# ESP32S31_RADIO register map
Vendor: Espressif; Series: ESP32-S31; File version: 3.52
Registers are 32-bit, read-write, no defined reset value unless marked. A register's access mark holds for its fields unless they carry their own. Offsets are from the block's base; [hi:lo] are bit positions; {n}, {i} and the like mark numbered series; 'fields as' and 'values as' point back to an identical list.

## BT_V3_2_CTE — Bluetooth direction-finding control words recovered from complete, independently named CTE accessors in the ESP32-S31 vendor baseband library. Only fields touched by those accessors are described; untouched bits remain unassigned.
Base 0x20102000
0x94 LC_8M_CONTROL — Bluetooth CTE LC 8-Mbit enable control.
  [0] LC_8M_ENABLE — The matched getter/setter pair reads and replaces bit 0.
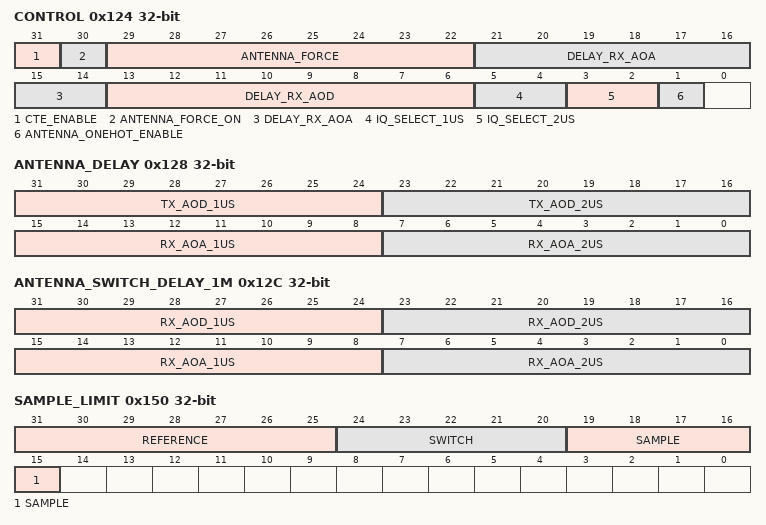
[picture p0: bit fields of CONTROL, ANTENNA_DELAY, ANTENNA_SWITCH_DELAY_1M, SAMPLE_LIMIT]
0x124 CONTROL — CTE antenna selection, receive-delay, IQ-selection and enable control. Bit 0 remains unassigned.
  [31] CTE_ENABLE — Complete ble_bb_cte_set_cte_en replaces bit 31 with the caller's Boolean image.
  [30] ANTENNA_FORCE_ON
  [29:22] ANTENNA_FORCE
  [21:14] DELAY_RX_AOA
  [13:6] DELAY_RX_AOD
  [5:4] IQ_SELECT_1US
  [3:2] IQ_SELECT_2US
  [1] ANTENNA_ONEHOT_ENABLE
0x128 ANTENNA_DELAY — Four independent eight-bit antenna delays selected by CTE direction and slot duration.
  [31:24] TX_AOD_1US, [23:16] TX_AOD_2US, [15:8] RX_AOA_1US, [7:0] RX_AOA_2US
0x12C ANTENNA_SWITCH_DELAY_1M — Four independent antenna-switch delays used by the ordinary CTE accessors.
  [31:24] RX_AOD_1US, [23:16] RX_AOD_2US, [15:8] RX_AOA_1US, [7:0] RX_AOA_2US
{0x130+2i} ANTENNA_MAP_ENTRY{i} (i=0..15) 16-bit wo — First sixteen halfword slots of the indexed antenna-map window. The complete setter copies caller-provided halfwords from index zero up to its input count; sixteen slots are the exact finite effects recovered under the current analysis bound, not a claim that the hardware window ends here.
  [15:0] IMAGE — Complete 16-bit antenna-map element; the encoding remains unknown.
0x150 SAMPLE_LIMIT — Three independently readable and writable CTE sampling-limit fields.
  [31:25] REFERENCE, [24:20] SWITCH, [19:15] SAMPLE
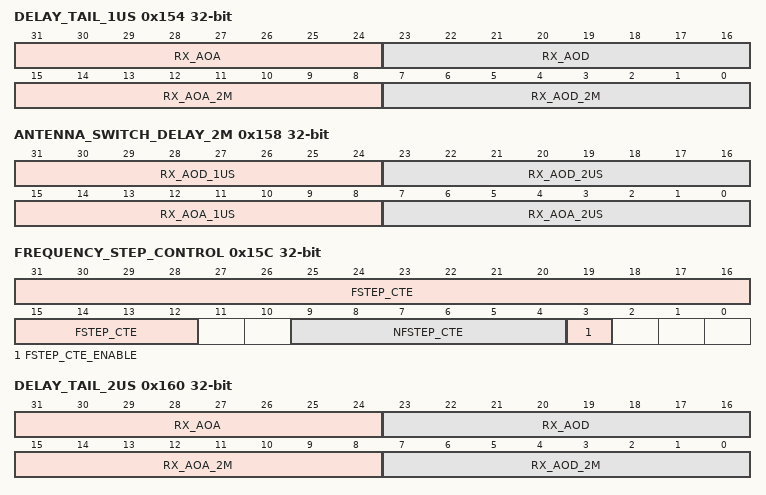
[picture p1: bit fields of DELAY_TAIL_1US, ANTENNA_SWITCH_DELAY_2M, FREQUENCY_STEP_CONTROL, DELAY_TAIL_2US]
0x154 DELAY_TAIL_1US — Four independent receive-tail delays for ordinary and 2-Mbit CTE operation with 1-microsecond slots.
  [31:24] RX_AOA, [23:16] RX_AOD, [15:8] RX_AOA_2M, [7:0] RX_AOD_2M
0x158 ANTENNA_SWITCH_DELAY_2M — Four independent antenna-switch delays used by the explicit 2-Mbit CTE accessors.
  fields as ANTENNA_SWITCH_DELAY_1M
0x15C FREQUENCY_STEP_CONTROL — CTE frequency-step enable, count and 20-bit step image. Bits 0:2 and 10:11 remain unassigned.
  [31:12] FSTEP_CTE, [9:4] NFSTEP_CTE, [3] FSTEP_CTE_ENABLE
0x160 DELAY_TAIL_2US — Four independent receive-tail delays for ordinary and 2-Mbit CTE operation with 2-microsecond slots.
  [31:24] RX_AOA, [23:16] RX_AOD, [15:8] RX_AOA_2M, [7:0] RX_AOD_2M
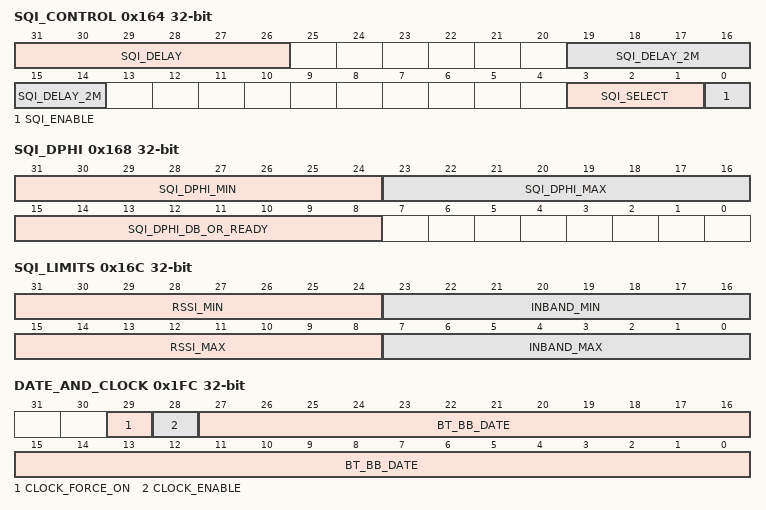
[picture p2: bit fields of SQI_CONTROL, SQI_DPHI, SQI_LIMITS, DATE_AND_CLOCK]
0x164 SQI_CONTROL — CTE signal-quality-indicator enable, selector and per-rate delay fields.
  [31:26] SQI_DELAY, [19:14] SQI_DELAY_2M, [3:1] SQI_SELECT, [0] SQI_ENABLE
0x168 SQI_DPHI — CTE SQI phase-difference thresholds/status. The byte at bits 15:8 is exposed both as SQI_DPHI_DB and, independently, bit 14 as SQI_READY; the non-overlapping model preserves that exact alias in one combined field.
  [31:24] SQI_DPHI_MIN
  [23:16] SQI_DPHI_MAX
  [15:8] SQI_DPHI_DB_OR_READY — Eight-bit SQI_DPHI_DB image; bit 6 of this field is also the independently addressable SQI_READY bit.
0x16C SQI_LIMITS — Four independent eight-bit in-band and RSSI thresholds used by the CTE SQI logic.
  [31:24] RSSI_MIN, [23:16] INBAND_MIN, [15:8] RSSI_MAX, [7:0] INBAND_MAX
0x1FC DATE_AND_CLOCK — Bluetooth baseband date image and CTE clock gates. Bits 31:30 remain unassigned.
  [29] CLOCK_FORCE_ON, [28] CLOCK_ENABLE, [27:0] BT_BB_DATE ro

## ZBBB_RADIO_CONTROL — Independently bounded words in the ZBBB window touched by complete Bluetooth baseband receive-setup and reset-idle leaves. Names describe only those exact operations; they do not claim that the physical block is owned exclusively by Bluetooth or assign a wider ZBBB protocol meaning.
Base 0x20102C00
0x00 RX_SETUP_IMAGE — bt_bb_rx_set preserves the low 12 bits and replaces bits 31:12 with the finite image 0x001CB; after the shared receive prefix, bt_bb_v2_init_cmplx(1) independently replaces the same field with 0x0019F.
  [31:12] CONFIG_IMAGE
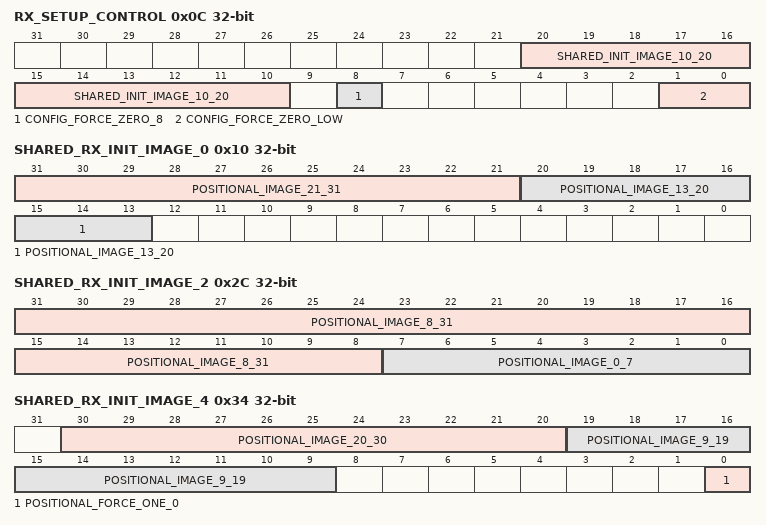
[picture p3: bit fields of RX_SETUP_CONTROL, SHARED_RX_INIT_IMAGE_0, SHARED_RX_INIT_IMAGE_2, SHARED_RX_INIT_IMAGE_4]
0x0C RX_SETUP_CONTROL — bt_bb_rx_set clears bit 8 and the low two-bit field through separate fresh-read RMW operations; the complete shared receive initializer independently replaces bits 10:20.
  [20:10] SHARED_INIT_IMAGE_10_20 — The complete shared receive initializer replaces bits 10:20 with the finite image 0x79C.
  [8] CONFIG_FORCE_ZERO_8
  [1:0] CONFIG_FORCE_ZERO_LOW
0x10 SHARED_RX_INIT_IMAGE_0 — The complete shared receive initializer replaces two disjoint positional fields with finite images while preserving every other bit.
  [31:21] POSITIONAL_IMAGE_21_31 — The complete initializer replaces bits 21:31 with the finite image 0x792.
  [20:13] POSITIONAL_IMAGE_13_20 — The complete initializer replaces bits 13:20 with the finite image 0xA6.
0x14 SHARED_RX_INIT_CONTROL_0 — The complete shared receive initializer clears one positional control bit and preserves the remainder of the word.
  [1] POSITIONAL_FORCE_ZERO_1 — The complete initializer clears bit 1.
0x18 SHARED_RX_INIT_IMAGE_1 — The complete shared receive initializer replaces the low eleven bits with one finite image.
  [10:0] POSITIONAL_IMAGE_0_10 — The complete initializer replaces bits 0:10 with the finite image 0x7A6.
0x28 SHARED_RX_INIT_CONTROL_1 — The complete shared receive initializer sets one positional control bit and preserves the remainder of the word.
  [30] POSITIONAL_FORCE_ONE_30 — The complete initializer sets bit 30.
0x2C SHARED_RX_INIT_IMAGE_2 — The complete shared receive initializer replaces the high twenty-four bits and low byte through two disjoint fresh-read updates.
  [31:8] POSITIONAL_IMAGE_8_31 — The complete initializer replaces bits 8:31 with the finite image 0x07A120.
  [7:0] POSITIONAL_IMAGE_0_7 — The complete initializer replaces bits 0:7 with the finite image 0xF1.
0x30 SHARED_RX_INIT_IMAGE_3 — The complete shared receive initializer replaces the high twenty-four bits with one finite image.
  [31:8] POSITIONAL_IMAGE_8_31 — The complete initializer replaces bits 8:31 with the finite image 0xF85EDF.
0x34 SHARED_RX_INIT_IMAGE_4 — The complete shared receive initializer replaces three disjoint positional fields with finite images.
  [30:20] POSITIONAL_IMAGE_20_30 — The complete initializer replaces bits 20:30 with the finite image 0x7E1.
  [19:9] POSITIONAL_IMAGE_9_19 — The complete initializer replaces bits 9:19 with the finite image 0x7ED.
  [0] POSITIONAL_FORCE_ONE_0 — The complete initializer sets bit 0.
0x38 SOFTWARE_RESET_IDLE_STATUS ro — bbmac_idle_for_swrst reports idle only when the observed low three-bit image equals one.
  [2:0] LOW_3_REQUIRED_IMAGE — The reset-idle predicate compares this exact field with the finite image 1.
